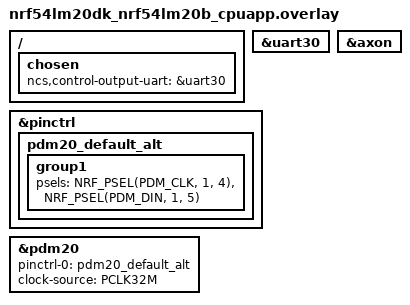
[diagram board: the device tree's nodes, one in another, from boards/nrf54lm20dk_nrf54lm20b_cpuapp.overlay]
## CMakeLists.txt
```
#
# ORIGEM: copia literal de arquivo do SDK — nao e codigo do curso.
#   Add-on  : Edge AI Add-on for nRF Connect SDK v2.3.0 (tag v2.3.0, commit 1c24f3a)
#   SDK     : nRF Connect SDK v3.4.0 (workspace do add-on)
#   Upstream: applications/ww_kws/CMakeLists.txt
#   Local   : C:/ncs/sdk-edge-ai/edge-ai/applications/ww_kws/CMakeLists.txt
#   Copiado : 2026-09-04 — curso nrf-manaus-2, modulo edge_ai/07_ww_kws
#
# Para conferir se divergiu do SDK:
#   diff <este arquivo> C:/ncs/sdk-edge-ai/edge-ai/applications/ww_kws/CMakeLists.txt
#
#
# Copyright (c) 2026 Nordic Semiconductor ASA
#
# SPDX-License-Identifier: LicenseRef-Nordic-5-Clause
#

cmake_minimum_required(VERSION 3.20.0)

find_package(Zephyr REQUIRED HINTS $ENV{ZEPHYR_BASE})
project(ww_kws)

target_sources(app PRIVATE
  src/main.c

  src/control_output.c
  src/dmic.c
  src/leds.c

  src/ww/wakeword.c
  src/ww/nrf_edgeai_generated/nrf_edgeai_user_model.c

  src/kws/kws.c
  src/kws/nrf_edgeai_generated/nrf_edgeai_user_model.c
)

target_sources_ifdef(CONFIG_MODELS_OBSERVABILITY_MDS app PRIVATE src/ble/ble_mds.c)
```

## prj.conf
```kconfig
#
# ORIGEM: copia literal de arquivo do SDK — nao e codigo do curso.
#   Add-on  : Edge AI Add-on for nRF Connect SDK v2.3.0 (tag v2.3.0, commit 1c24f3a)
#   SDK     : nRF Connect SDK v3.4.0 (workspace do add-on)
#   Upstream: applications/ww_kws/prj.conf
#   Local   : C:/ncs/sdk-edge-ai/edge-ai/applications/ww_kws/prj.conf
#   Copiado : 2026-09-04 — curso nrf-manaus-2, modulo edge_ai/07_ww_kws
#
# Para conferir se divergiu do SDK:
#   diff <este arquivo> C:/ncs/sdk-edge-ai/edge-ai/applications/ww_kws/prj.conf
#
#
# Copyright (c) 2026 Nordic Semiconductor
#
# SPDX-License-Identifier: LicenseRef-Nordic-5-Clause
#

# nRF Edge AI
CONFIG_NRF_EDGEAI=y

# nRF Edge AI dependencies
CONFIG_NRF_AXON=y
CONFIG_FPU=y

# Size of interlayer buffer to fit model
CONFIG_NRF_AXON_INTERLAYER_BUFFER_SIZE=6656

# Size of psum buffer to fit model
CONFIG_NRF_AXON_PSUM_BUFFER_SIZE=0

# Enable sensor, button and LED libraries
CONFIG_GPIO=y
CONFIG_AUDIO=y
CONFIG_AUDIO_DMIC=y

# Enable logging and assert
CONFIG_LOG=y
CONFIG_CONSOLE=y
CONFIG_SERIAL=y
CONFIG_ASSERT=y

CONFIG_UART_ASYNC_API=y

CONFIG_WW_PROBABILITY_THRESHOLD=800
```

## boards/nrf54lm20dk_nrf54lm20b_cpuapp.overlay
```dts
/*
 * ORIGEM: copia literal de arquivo do SDK — nao e codigo do curso.
 *   Add-on  : Edge AI Add-on for nRF Connect SDK v2.3.0 (tag v2.3.0, commit 1c24f3a)
 *   SDK     : nRF Connect SDK v3.4.0 (workspace do add-on)
 *   Upstream: applications/ww_kws/boards/nrf54lm20dk_nrf54lm20b_cpuapp.overlay
 *   Local   : C:/ncs/sdk-edge-ai/edge-ai/applications/ww_kws/boards/nrf54lm20dk_nrf54lm20b_cpuapp.overlay
 *   Copiado : 2026-09-04 — curso nrf-manaus-2, modulo edge_ai/07_ww_kws
 *
 * Para conferir se divergiu do SDK:
 *   diff <este arquivo> C:/ncs/sdk-edge-ai/edge-ai/applications/ww_kws/boards/nrf54lm20dk_nrf54lm20b_cpuapp.overlay
 */
/*
 * Copyright (c) 2026 Nordic Semiconductor ASA
 *
 * SPDX-License-Identifier: LicenseRef-Nordic-5-Clause
 */

/ {
	chosen {
		ncs,control-output-uart = &uart30;
	};
};

&uart30 {
	status = "okay";
};

&pinctrl {
	pdm20_default_alt: pdm20_default_alt {
		group1 {
			psels = <NRF_PSEL(PDM_CLK, 1, 4)>,
				<NRF_PSEL(PDM_DIN, 1, 5)>;
		};
	};
};

dmic_dev: &pdm20 {
	status = "okay";
	pinctrl-0 = <&pdm20_default_alt>;
	pinctrl-names = "default";
	clock-source = "PCLK32M";
};

&axon {
	status = "okay";
};
```

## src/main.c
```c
/*
 * ORIGEM: copia literal de arquivo do SDK — nao e codigo do curso.
 *   Add-on  : Edge AI Add-on for nRF Connect SDK v2.3.0 (tag v2.3.0, commit 1c24f3a)
 *   SDK     : nRF Connect SDK v3.4.0 (workspace do add-on)
 *   Upstream: applications/ww_kws/src/main.c
 *   Local   : C:/ncs/sdk-edge-ai/edge-ai/applications/ww_kws/src/main.c
 *   Copiado : 2026-09-04 — curso nrf-manaus-2, modulo edge_ai/07_ww_kws
 *
 * Para conferir se divergiu do SDK:
 *   diff <este arquivo> C:/ncs/sdk-edge-ai/edge-ai/applications/ww_kws/src/main.c
 */
/*
 * Copyright (c) 2026 Nordic Semiconductor ASA
 *
 * SPDX-License-Identifier: LicenseRef-Nordic-5-Clause
 */

#include <stddef.h>
#include <stdint.h>

#include <zephyr/audio/dmic.h>
#include <zephyr/device.h>
#include <zephyr/devicetree.h>
#include <zephyr/logging/log.h>

#include "ble/ble_mds.h"
#include "control_output.h"
#include "dmic.h"
#include "kws/kws.h"
#include "leds.h"
#include "ww/wakeword.h"

LOG_MODULE_REGISTER(main);

#define DMIC_READ_TIMEOUT 100

static const struct device *const dmic_dev = DEVICE_DT_GET(DT_NODELABEL(dmic_dev));

static int ww_loop(void)
{
	int err;
	void *audio_buffer;
	size_t audio_buffer_size;
	bool ww_detected;

	ww_reset();

	print_control_output((struct control_message){CONTROL_MESSAGE_WAITING_WW});

	while (true) {
		err = dmic_read(dmic_dev, 0, &audio_buffer, &audio_buffer_size, DMIC_READ_TIMEOUT);
		if (err < 0) {
			LOG_ERR("Failed to read from DMIC (err %d)", err);
			return err;
		}

		err = ww_process(audio_buffer, DMIC_SAMPLES_IN_BLOCK, &ww_detected);
		if (err == -EBUSY) {
			/* More data is needed. */
			continue;
		} else if (err < 0) {
			LOG_ERR("Wakeword detection failed (err %d)", err);
			return err;
		}

		if (ww_detected) {
			print_control_output((struct control_message){CONTROL_MESSAGE_WW_DETECTED});
			if (IS_ENABLED(CONFIG_APP_MODE_WW_ONLY)) {
				leds_blink_led0();
			} else {
				return 0;
			}
		}
	}
}

static int kws_loop(void)
{
	int err;
	void *audio_buffer;
	size_t audio_buffer_size;
	struct kws_prediction prediction;

	uint32_t spotting_timeout = k_uptime_get_32() + CONFIG_KWS_PERIOD_MS;

	kws_reset();

	print_control_output((struct control_message){.type = CONTROL_MESSAGE_WAITING_KW});

	while (IS_ENABLED(CONFIG_APP_MODE_KWS_ONLY) || spotting_timeout > k_uptime_get_32()) {
		err = dmic_read(dmic_dev, 0, &audio_buffer, &audio_buffer_size, DMIC_READ_TIMEOUT);
		if (err < 0) {
			LOG_ERR("Failed to read from DMIC (err %d)", err);
			return err;
		}

		err = kws_process(audio_buffer, DMIC_SAMPLES_IN_BLOCK, &prediction);
		if (err == -EBUSY) {
			/* More data is needed. */
			continue;
		} else if (err) {
			LOG_ERR("Keyword spotting failed (err %d)", err);
			return err;
		}

		if (prediction.valid) {
			leds_blink_led1();
			spotting_timeout = k_uptime_get_32() + CONFIG_KWS_PERIOD_MS;
			print_control_output(
				(struct control_message){.type = CONTROL_MESSAGE_KW_SPOTTED,
							 .kw_class = prediction.class,
							 .name = prediction.name});
		}
	}

	print_control_output((struct control_message){.type = CONTROL_MESSAGE_TIMEOUT_KWS});

	return 0;
}

int main(void)
{
	int err;

	err = dmic_init();
	if (err) {
		return err;
	}

	err = leds_init();
	if (err) {
		return err;
	}

	err = control_output_init();
	if (err) {
		return err;
	}

	if (IS_ENABLED(CONFIG_APP_MODE_WW_GATED_KWS) || IS_ENABLED(CONFIG_APP_MODE_WW_ONLY)) {
		err = ww_init();
		if (err) {
			return err;
		}
	}

	if (IS_ENABLED(CONFIG_APP_MODE_WW_GATED_KWS) || IS_ENABLED(CONFIG_APP_MODE_KWS_ONLY)) {
		err = kws_init();
		if (err) {
			return err;
		}
	}

	err = init_app_ble();
	if (err) {
		return err;
	}

	LOG_INF("Initialization completed, check output on VCOM0");

	err = dmic_trigger(dmic_dev, DMIC_TRIGGER_START);
	if (err < 0) {
		LOG_ERR("Failed to start DMIC (err %d)", err);
		return err;
	}

	while (true) {
		if (IS_ENABLED(CONFIG_APP_MODE_WW_GATED_KWS) ||
		    IS_ENABLED(CONFIG_APP_MODE_WW_ONLY)) {
			err = ww_loop();
			if (err) {
				return err;
			}
		}

		if (IS_ENABLED(CONFIG_APP_MODE_WW_GATED_KWS)) {
			leds_on_led0();
		}

		if (IS_ENABLED(CONFIG_APP_MODE_WW_GATED_KWS) ||
		    IS_ENABLED(CONFIG_APP_MODE_KWS_ONLY)) {
			err = kws_loop();
			if (err) {
				return err;
			}
		}

		if (IS_ENABLED(CONFIG_APP_MODE_WW_GATED_KWS)) {
			leds_off_led0();
		}
	}

	return 0;
}
```

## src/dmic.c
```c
/*
 * ORIGEM: copia literal de arquivo do SDK — nao e codigo do curso.
 *   Add-on  : Edge AI Add-on for nRF Connect SDK v2.3.0 (tag v2.3.0, commit 1c24f3a)
 *   SDK     : nRF Connect SDK v3.4.0 (workspace do add-on)
 *   Upstream: applications/ww_kws/src/dmic.c
 *   Local   : C:/ncs/sdk-edge-ai/edge-ai/applications/ww_kws/src/dmic.c
 *   Copiado : 2026-09-04 — curso nrf-manaus-2, modulo edge_ai/07_ww_kws
 *
 * Para conferir se divergiu do SDK:
 *   diff <este arquivo> C:/ncs/sdk-edge-ai/edge-ai/applications/ww_kws/src/dmic.c
 */
/*
 * Copyright (c) 2026 Nordic Semiconductor ASA
 *
 * SPDX-License-Identifier: LicenseRef-Nordic-5-Clause
 */

#include <stddef.h>

#include <zephyr/audio/dmic.h>
#include <zephyr/device.h>
#include <zephyr/devicetree.h>
#include <zephyr/kernel.h>
#include <zephyr/logging/log.h>

#include "dmic.h"

LOG_MODULE_REGISTER(dmic);

#define BLOCK_SIZE (DMIC_SAMPLE_BYTES * DMIC_SAMPLES_IN_BLOCK)

K_MEM_SLAB_DEFINE_STATIC(dmic_mem_slab, BLOCK_SIZE, 4, 4);

int dmic_init(void)
{
	int err;
	const struct device *const dmic_dev = DEVICE_DT_GET(DT_NODELABEL(dmic_dev));

	if (!device_is_ready(dmic_dev)) {
		LOG_ERR("Device is not ready");
		return -ENODEV;
	}

	struct pcm_stream_cfg stream = {
		.pcm_rate = DMIC_PCM_RATE,
		.pcm_width = DMIC_SAMPLE_BYTES * 8,
		.block_size = BLOCK_SIZE,
		.mem_slab = &dmic_mem_slab,
	};
	struct dmic_cfg cfg = {
		.io = {
			.min_pdm_clk_freq = 1000000,
			.max_pdm_clk_freq = 3250000,
			.min_pdm_clk_dc = 40,
			.max_pdm_clk_dc = 60,
		},
		.streams = &stream,
		.channel = {
			.req_chan_map_lo = dmic_build_channel_map(0, 0, PDM_CHAN_LEFT),
			.req_chan_map_hi = 0,
			.req_num_chan = 1,
			.req_num_streams = 1,
		},
	};

	err = dmic_configure(dmic_dev, &cfg);
	if (err < 0) {
		LOG_ERR("Failed to configure (err %d)", err);
		return err;
	}

	return 0;
}

void free_dmic_buffer(void *buffer)
{
	k_mem_slab_free(&dmic_mem_slab, buffer);
}
```
